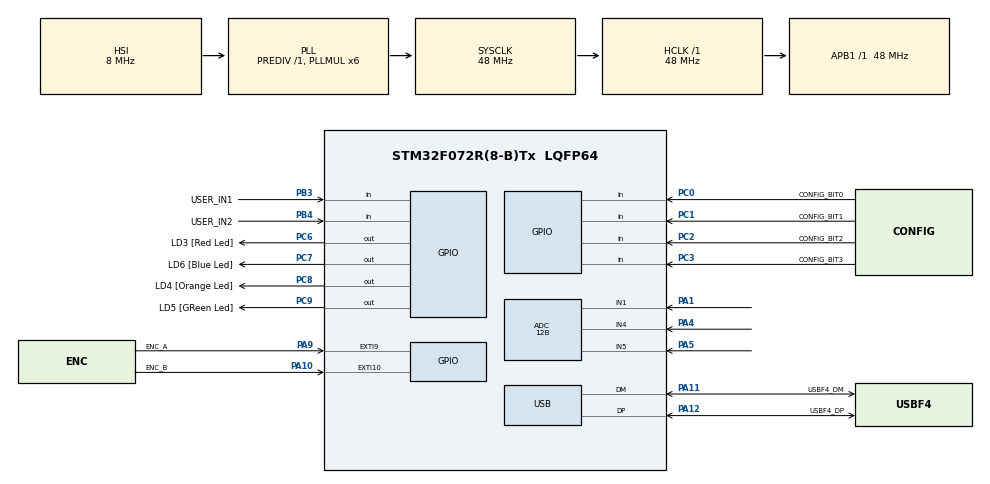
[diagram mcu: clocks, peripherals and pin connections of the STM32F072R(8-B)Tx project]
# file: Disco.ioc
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ADC.ClockPrescaler=ADC_CLOCK_SYNC_PCLK_DIV4
ADC.ContinuousConvMode=ENABLE
ADC.DMAContinuousRequests=ENABLE
ADC.Resolution=ADC_RESOLUTION_12B
ADC.SamplingTime=ADC_SAMPLETIME_28CYCLES_5
ADC.ScanConvMode=ADC_SCAN_DIRECTION_FORWARD
Dma.ADC.0.Direction=DMA_PERIPH_TO_MEMORY
Dma.ADC.0.Instance=DMA1_Channel1
Dma.ADC.0.MemDataAlignment=DMA_MDATAALIGN_WORD
Dma.ADC.0.MemInc=DMA_MINC_ENABLE
Dma.ADC.0.Mode=DMA_CIRCULAR
Dma.ADC.0.PeriphDataAlignment=DMA_PDATAALIGN_WORD
Dma.ADC.0.PeriphInc=DMA_PINC_DISABLE
Dma.ADC.0.Priority=DMA_PRIORITY_LOW
Dma.Request0=ADC
Mcu.Family=STM32F0
Mcu.Name=STM32F072R(8-B)Tx
Mcu.Package=LQFP64
NVIC.DMA1_Channel1_IRQn=true\:0\:0\:true\:false\:true\:false\:true
NVIC.EXTI4_15_IRQn=true\:0\:0\:true\:false\:true\:true\:true
NVIC.TIM14_IRQn=true\:0\:0\:true\:false\:true\:true\:true
NVIC.USB_IRQn=true\:0\:0\:true\:false\:true\:false\:true
PA1.Mode=IN1
PA1.Signal=ADC_IN1
PA10.GPIO_Label=ENC_B
PA10.GPIO_ModeDefaultEXTI=GPIO_MODE_IT_RISING_FALLING
PA10.GPIO_PuPd=GPIO_PULLUP
PA10.Signal=GPXTI10
PA11.GPIO_Label=USBF4_DM
PA11.Mode=Device
PA11.Signal=USB_DM
PA12.GPIO_Label=USBF4_DP
PA12.Mode=Device
PA12.Signal=USB_DP
PA13.GPIO_Label=SWDIO
PA13.Mode=Serial_Wire
PA13.Signal=SYS_SWDIO
PA14.GPIO_Label=SWCLK
PA14.Mode=Serial_Wire
PA14.Signal=SYS_SWCLK
PA4.Mode=IN4
PA4.Signal=ADC_IN4
PA5.Mode=IN5
PA5.Signal=ADC_IN5
PA9.GPIO_Label=ENC_A
PA9.GPIO_ModeDefaultEXTI=GPIO_MODE_IT_RISING_FALLING
PA9.GPIO_PuPd=GPIO_PULLUP
PA9.Signal=GPXTI9
PB3.GPIO_Label=USER_IN1
PB3.Signal=GPIO_Input
PB4.GPIO_Label=USER_IN2
PB4.Signal=GPIO_Input
PC0.GPIO_Label=CONFIG_BIT0
PC0.Signal=GPIO_Input
PC1.GPIO_Label=CONFIG_BIT1
PC1.Signal=GPIO_Input
PC2.GPIO_Label=CONFIG_BIT2
PC2.Signal=GPIO_Input
PC3.GPIO_Label=CONFIG_BIT3
PC3.Signal=GPIO_Input
PC6.GPIO_Label=LD3 [Red Led]
PC6.Signal=GPIO_Output
PC7.GPIO_Label=LD6 [Blue Led]
PC7.Signal=GPIO_Output
PC8.GPIO_Label=LD4 [Orange Led]
PC8.Signal=GPIO_Output
PC9.GPIO_Label=LD5 [GReen Led]
PC9.Signal=GPIO_Output
ProjectManager.HeapSize=0x200
ProjectManager.StackSize=0x400
ProjectManager.TargetToolchain=STM32CubeIDE
RCC.AHBFreq_Value=48000000
RCC.APB1Freq_Value=48000000
RCC.APB1TimFreq_Value=48000000
RCC.HCLKFreq_Value=48000000
RCC.PLLMUL=RCC_PLL_MUL6
RCC.SYSCLKFreq_VALUE=48000000
RCC.SYSCLKSource=RCC_SYSCLKSOURCE_PLLCLK
TIM14.Period=64865
TIM14.Prescaler=74
TIM2.Prescaler=48
USB.phy_itface=PCD_PHY_EMBEDDED
USB.speed=PCD_SPEED_FULL
USB_DEVICE.CLASS_NAME_FS=CDC
USB_DEVICE.VirtualMode=Cdc
USB_DEVICE.VirtualModeFS=Cdc_FS
VP_TIM14_VS_ClockSourceINT.Mode=Enable_Timer
VP_TIM2_VS_ClockSourceINT.Mode=Internal
VP_USB_DEVICE_VS_USB_DEVICE_CDC_FS.Mode=CDC_FS
board=STM32F072B-DISCO

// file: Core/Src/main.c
/* USER CODE BEGIN Header */
/**
  ******************************************************************************
  * @file           : main.c
  * @brief          : Main program body
  ******************************************************************************
  * @attention
  *
  * <h2><center>&copy; Copyright (c) 2020 STMicroelectronics.
  * All rights reserved.</center></h2>
  *
  * This software component is licensed by ST under BSD 3-Clause license,
  * the "License"; You may not use this file except in compliance with the
  * License. You may obtain a copy of the License at:
  *                        opensource.org/licenses/BSD-3-Clause
  *
  ******************************************************************************
  */
/* USER CODE END Header */
#include "main.h"
#include "usb_device.h"

/* USER CODE BEGIN Includes */
#include "acquisition.h"
#include "outputs.h"
#include "panda_usb_device.h"
/* USER CODE END Includes */

ADC_HandleTypeDef hadc;
DMA_HandleTypeDef hdma_adc;

TIM_HandleTypeDef htim2;
TIM_HandleTypeDef htim14;

void SystemClock_Config(void);
static void MX_GPIO_Init(void);
static void MX_DMA_Init(void);
static void MX_TIM14_Init(void);
static void MX_ADC_Init(void);
static void MX_TIM2_Init(void);

int main(void)
{

  /* MCU Configuration--------------------------------------------------------*/

  /* Reset of all peripherals, Initializes the Flash interface and the Systick. */
  HAL_Init();

  /* Configure the system clock */
  SystemClock_Config();

  /* Initialize all configured peripherals */
  MX_GPIO_Init();
  MX_DMA_Init();
  MX_TIM14_Init();
  MX_USB_DEVICE_Init();
  MX_ADC_Init();
  MX_TIM2_Init();
  /* USER CODE BEGIN 2 */

  usb_init();
  outputsInit(&htim14);
  acquisitionInit(&hadc, &htim2);
  statusLedBlink();

  /* USER CODE END 2 */

  /* Infinite loop */
  /* USER CODE BEGIN WHILE */
  while (1)
  {
	  usbController();
	  userLedController();

    /* USER CODE END WHILE */

  }
}

void SystemClock_Config(void)
{
  RCC_OscInitTypeDef RCC_OscInitStruct = {0};
  RCC_ClkInitTypeDef RCC_ClkInitStruct = {0};
  RCC_PeriphCLKInitTypeDef PeriphClkInit = {0};

  /** Initializes the RCC Oscillators according to the specified parameters
  * in the RCC_OscInitTypeDef structure.
  */
  RCC_OscInitStruct.OscillatorType = RCC_OSCILLATORTYPE_HSI|RCC_OSCILLATORTYPE_HSI48;
  RCC_OscInitStruct.HSIState = RCC_HSI_ON;
  RCC_OscInitStruct.HSI48State = RCC_HSI48_ON;
  RCC_OscInitStruct.HSICalibrationValue = RCC_HSICALIBRATION_DEFAULT;
  RCC_OscInitStruct.PLL.PLLState = RCC_PLL_ON;
  RCC_OscInitStruct.PLL.PLLSource = RCC_PLLSOURCE_HSI;
  RCC_OscInitStruct.PLL.PLLMUL = RCC_PLL_MUL6;
  RCC_OscInitStruct.PLL.PREDIV = RCC_PREDIV_DIV1;
  if (HAL_RCC_OscConfig(&RCC_OscInitStruct) != HAL_OK)
  {
    Error_Handler();
  }
  /** Initializes the CPU, AHB and APB buses clocks
  */
  RCC_ClkInitStruct.ClockType = RCC_CLOCKTYPE_HCLK|RCC_CLOCKTYPE_SYSCLK
                              |RCC_CLOCKTYPE_PCLK1;
  RCC_ClkInitStruct.SYSCLKSource = RCC_SYSCLKSOURCE_PLLCLK;
  RCC_ClkInitStruct.AHBCLKDivider = RCC_SYSCLK_DIV1;
  RCC_ClkInitStruct.APB1CLKDivider = RCC_HCLK_DIV1;

  if (HAL_RCC_ClockConfig(&RCC_ClkInitStruct, FLASH_LATENCY_1) != HAL_OK)
  {
    Error_Handler();
  }
  PeriphClkInit.PeriphClockSelection = RCC_PERIPHCLK_USB;
  PeriphClkInit.UsbClockSelection = RCC_USBCLKSOURCE_HSI48;

  if (HAL_RCCEx_PeriphCLKConfig(&PeriphClkInit) != HAL_OK)
  {
    Error_Handler();
  }
}

static void MX_ADC_Init(void)
{

  ADC_ChannelConfTypeDef sConfig = {0};

  /** Configure the global features of the ADC (Clock, Resolution, Data Alignment and number of conversion)
  */
  hadc.Instance = ADC1;
  hadc.Init.ClockPrescaler = ADC_CLOCK_SYNC_PCLK_DIV4;
  hadc.Init.Resolution = ADC_RESOLUTION_12B;
  hadc.Init.DataAlign = ADC_DATAALIGN_RIGHT;
  hadc.Init.ScanConvMode = ADC_SCAN_DIRECTION_FORWARD;
  hadc.Init.EOCSelection = ADC_EOC_SINGLE_CONV;
  hadc.Init.LowPowerAutoWait = DISABLE;
  hadc.Init.LowPowerAutoPowerOff = DISABLE;
  hadc.Init.ContinuousConvMode = ENABLE;
  hadc.Init.DiscontinuousConvMode = DISABLE;
  hadc.Init.ExternalTrigConv = ADC_SOFTWARE_START;
  hadc.Init.ExternalTrigConvEdge = ADC_EXTERNALTRIGCONVEDGE_NONE;
  hadc.Init.DMAContinuousRequests = ENABLE;
  hadc.Init.Overrun = ADC_OVR_DATA_PRESERVED;
  if (HAL_ADC_Init(&hadc) != HAL_OK)
  {
    Error_Handler();
  }
  /** Configure for the selected ADC regular channel to be converted.
  */
  sConfig.Channel = ADC_CHANNEL_1;
  sConfig.Rank = ADC_RANK_CHANNEL_NUMBER;
  sConfig.SamplingTime = ADC_SAMPLETIME_28CYCLES_5;
  if (HAL_ADC_ConfigChannel(&hadc, &sConfig) != HAL_OK)
  {
    Error_Handler();
  }
  /** Configure for the selected ADC regular channel to be converted.
  */
  sConfig.Channel = ADC_CHANNEL_4;
  if (HAL_ADC_ConfigChannel(&hadc, &sConfig) != HAL_OK)
  {
    Error_Handler();
  }
  /** Configure for the selected ADC regular channel to be converted.
  */
  sConfig.Channel = ADC_CHANNEL_5;
  if (HAL_ADC_ConfigChannel(&hadc, &sConfig) != HAL_OK)
  {
    Error_Handler();
  }

}

static void MX_TIM2_Init(void)
{

  TIM_ClockConfigTypeDef sClockSourceConfig = {0};
  TIM_MasterConfigTypeDef sMasterConfig = {0};

  htim2.Instance = TIM2;
  htim2.Init.Prescaler = 48;
  htim2.Init.CounterMode = TIM_COUNTERMODE_UP;
  htim2.Init.Period = 4294967295;
  htim2.Init.ClockDivision = TIM_CLOCKDIVISION_DIV1;
  htim2.Init.AutoReloadPreload = TIM_AUTORELOAD_PRELOAD_DISABLE;
  if (HAL_TIM_Base_Init(&htim2) != HAL_OK)
  {
    Error_Handler();
  }
  sClockSourceConfig.ClockSource = TIM_CLOCKSOURCE_INTERNAL;
  if (HAL_TIM_ConfigClockSource(&htim2, &sClockSourceConfig) != HAL_OK)
  {
    Error_Handler();
  }
  sMasterConfig.MasterOutputTrigger = TIM_TRGO_RESET;
  sMasterConfig.MasterSlaveMode = TIM_MASTERSLAVEMODE_DISABLE;
  if (HAL_TIMEx_MasterConfigSynchronization(&htim2, &sMasterConfig) != HAL_OK)
  {
    Error_Handler();
  }

}

static void MX_TIM14_Init(void)
{

  htim14.Instance = TIM14;
  htim14.Init.Prescaler = 74;
  htim14.Init.CounterMode = TIM_COUNTERMODE_UP;
  htim14.Init.Period = 64865;
  htim14.Init.ClockDivision = TIM_CLOCKDIVISION_DIV1;
  htim14.Init.AutoReloadPreload = TIM_AUTORELOAD_PRELOAD_DISABLE;
  if (HAL_TIM_Base_Init(&htim14) != HAL_OK)
  {
    Error_Handler();
  }

}

static void MX_DMA_Init(void)
{

  /* DMA controller clock enable */
  __HAL_RCC_DMA1_CLK_ENABLE();

  /* DMA interrupt init */
  /* DMA1_Channel1_IRQn interrupt configuration */
  HAL_NVIC_SetPriority(DMA1_Channel1_IRQn, 0, 0);
  HAL_NVIC_EnableIRQ(DMA1_Channel1_IRQn);

}

static void MX_GPIO_Init(void)
{
  GPIO_InitTypeDef GPIO_InitStruct = {0};

  /* GPIO Ports Clock Enable */
  __HAL_RCC_GPIOC_CLK_ENABLE();
  __HAL_RCC_GPIOA_CLK_ENABLE();
  __HAL_RCC_GPIOB_CLK_ENABLE();

  /*Configure GPIO pin Output Level */
  HAL_GPIO_WritePin(GPIOC, LD3_Pin|LD6_Pin|LD4_Pin|LD5_Pin, GPIO_PIN_RESET);

  /*Configure GPIO pins : CONFIG_BIT0_Pin CONFIG_BIT1_Pin CONFIG_BIT2_Pin CONFIG_BIT3_Pin */
  GPIO_InitStruct.Pin = CONFIG_BIT0_Pin|CONFIG_BIT1_Pin|CONFIG_BIT2_Pin|CONFIG_BIT3_Pin;
  GPIO_InitStruct.Mode = GPIO_MODE_INPUT;
  GPIO_InitStruct.Pull = GPIO_NOPULL;
  HAL_GPIO_Init(GPIOC, &GPIO_InitStruct);

  /*Configure GPIO pins : LD3_Pin LD6_Pin LD4_Pin LD5_Pin */
  GPIO_InitStruct.Pin = LD3_Pin|LD6_Pin|LD4_Pin|LD5_Pin;
  GPIO_InitStruct.Mode = GPIO_MODE_OUTPUT_PP;
  GPIO_InitStruct.Pull = GPIO_NOPULL;
  GPIO_InitStruct.Speed = GPIO_SPEED_FREQ_LOW;
  HAL_GPIO_Init(GPIOC, &GPIO_InitStruct);

  /*Configure GPIO pins : ENC_A_Pin ENC_B_Pin */
  GPIO_InitStruct.Pin = ENC_A_Pin|ENC_B_Pin;
  GPIO_InitStruct.Mode = GPIO_MODE_IT_RISING_FALLING;
  GPIO_InitStruct.Pull = GPIO_PULLUP;
  HAL_GPIO_Init(GPIOA, &GPIO_InitStruct);

  /*Configure GPIO pins : USER_IN1_Pin USER_IN2_Pin */
  GPIO_InitStruct.Pin = USER_IN1_Pin|USER_IN2_Pin;
  GPIO_InitStruct.Mode = GPIO_MODE_INPUT;
  GPIO_InitStruct.Pull = GPIO_NOPULL;
  HAL_GPIO_Init(GPIOB, &GPIO_InitStruct);

  /* EXTI interrupt init*/
  HAL_NVIC_SetPriority(EXTI4_15_IRQn, 0, 0);
  HAL_NVIC_EnableIRQ(EXTI4_15_IRQn);

}

/* USER CODE BEGIN 4 */
void HAL_GPIO_EXTI_Callback(uint16_t GPIO_Pin)
{
  if(GPIO_Pin == ENC_A_Pin || GPIO_Pin == ENC_B_Pin){
	  encoderController();
  }

}
/* USER CODE END 4 */

void Error_Handler(void)
{
}

/************************ (C) COPYRIGHT STMicroelectronics *****END OF FILE****/
